AUTOSAR XML (schema 314)
package /ComponentType
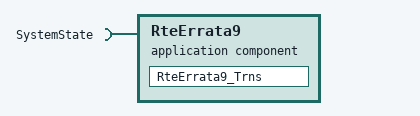
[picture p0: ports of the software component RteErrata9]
  application software component type RteErrata9  # This SWC contains definitions required to workaround Rte Generation errata following: 1) ESCAN00059438AN00059438 (corrected in Rte 2.22.00)
    require port SystemState: required-interface=SystemState
  internal behavior RteErrata9_InternalBehavior: component=RteErrata9, port-api-option{enable-take-address=false, indirect-api=false, port=SystemState}
    4 x mode switch event, all with start-on-event=RteErrata9_Trns, activation=ENTRY:
      MST_RteErrata9_Trns_0: mode=SystemState.Mode.DISABLE
      MST_RteErrata9_Trns_1: mode=SystemState.Mode.OFF
      MST_RteErrata9_Trns_2: mode=SystemState.Mode.WARMINIT
      MST_RteErrata9_Trns_3: mode=SystemState.Mode.OPERATE
    runnable RteErrata9_Trns
  swc implementation RteErrata9_Implementation: behavior=RteErrata9_InternalBehavior
    code-descriptors:
      code Code: type=SRC
